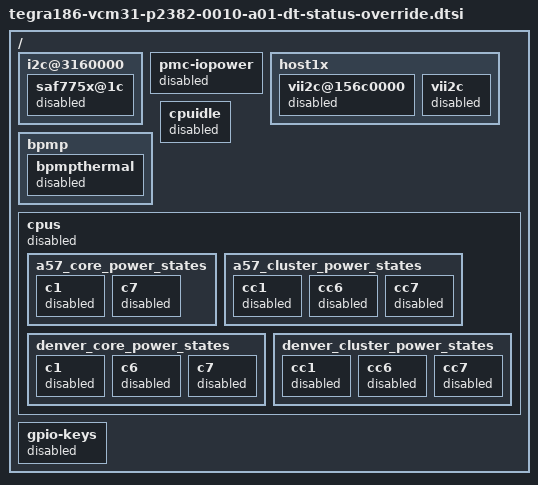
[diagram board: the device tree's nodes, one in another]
/*
 * tegra186-vcm31-p2382-0010-a01-dt-status-override.dtsi:
 *
 * Copyright (c) 2015, NVIDIA CORPORATION.  All rights reserved.
 *
 * This program is free software; you can redistribute it and/or modify
 * it under the terms of the GNU General Public License as published by
 * the Free Software Foundation; version 2 of the License.
 *
 * This program is distributed in the hope that it will be useful, but WITHOUT
 * ANY WARRANTY; without even the implied warranty of MERCHANTABILITY or
 * FITNESS FOR A PARTICULAR PURPOSE.  See the GNU General Public License for
 * more details.
 */

/ {
	i2c@3160000 {
		saf775x@1c {
			status = "disabled";
		};
	};

	pmc-iopower {
		status = "disabled";
	};

	host1x {

		vii2c@156c0000 {
			status = "disabled";
		};


		vii2c {
			status = "disabled";
		};
	};

	bpmp {
		bpmpthermal {
			status = "disabled";
		};
	};

	cpuidle {
		status = "disabled";
	};

	cpus {
		status = "disabled";

		a57_core_power_states {

			c1 {
				status = "disabled";
			};

			c7 {
				status = "disabled";
			};
		};

		a57_cluster_power_states {

			cc1 {
				status = "disabled";
			};

			cc6 {
				status = "disabled";
			};

			cc7 {
				status = "disabled";
			};
		};

		denver_core_power_states {

			c1 {
				status = "disabled";
			};

			c6 {
				status = "disabled";
			};

			c7 {
				status = "disabled";
			};
		};

		denver_cluster_power_states {

			cc1 {
				status = "disabled";
			};

			cc6 {
				status = "disabled";
			};

			cc7 {
				status = "disabled";
			};
		};
	};

	gpio-keys {
		status = "disabled";
	};
};
